# Z20K14xM register map
Vendor: Zhixin Semiconductor; Series: Z20K14xM; File version: 0.1.0
CPU: CM4 r0p1, little endian, no MPU, FPU, 4 interrupt priority bits
Registers are 32-bit, read-write, reset 0x0 unless marked. A register's access mark holds for its fields unless they carry their own. Offsets are from the block's base; [hi:lo] are bit positions; {n}, {i} and the like mark numbered series; 'fields as' and 'values as' point back to an identical list.

## PORT
Base 0x40049000
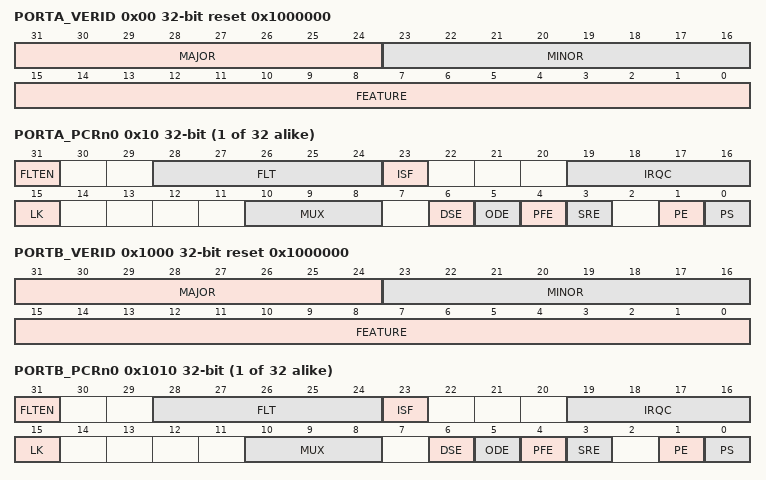
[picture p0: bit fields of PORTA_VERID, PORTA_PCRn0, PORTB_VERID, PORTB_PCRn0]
0x00 PORTA_VERID ro reset 0x1000000 — Port Version Number(PORTA_VERID)
  [31:24] MAJOR — Major Version Number
  [23:16] MINOR — Minor Version Number
  [15:0] FEATURE — Module Identification Number
0x04 PORTA_PARAM ro — PORT Parameter Register(PORTA_PARAM)
0x08 PORTA_GLBDAT — Global Pin Data Register(PORTA_GLBDAT)
  [31:0] GPWD — Global Pin Write Data
0x0C PORTA_GLBCTL wo — Global Pin Control Register(PORTA_GLBCTL)
  [31:0] GPWE — Global Pin Write Enable
{0x10+4i} PORTA_PCRn{i} (i=0..31) — Pin Control Register(PORTA_PCRn)
  [31] FLTEN — filter enable
  [28:24] FLT — filter configuration
  [23] ISF — Interrupt Status Flag
  [19:16] IRQC — Interrupt Configuration
  [15] LK — Lock Register
  [10:8] MUX — Pin Mux Control
  [6] DSE — Drive Strength Enable
  [5] ODE — Open Drain Enable
  [4] PFE — Passive Filter Enable
  [3] SRE — Slew Rate Enable
  [1] PE — Pull Enable
  [0] PS — Pull Select
0x90 PORTA_IRQFLG — Interrupt Status Flag Register (PORTA_IRQFLG)
  [31:0] ISF — Interrupt Status Flag
0x1000 PORTB_VERID ro reset 0x1000000 — Port Version Number(PORTB_VERID)
  fields as PORTA_VERID
0x1004 PORTB_PARAM ro — PORT Parameter Register(PORTB_PARAM)
0x1008 PORTB_GLBDAT — Global Pin Data Register(PORTB_GLBDAT)
  [31:0] GPWD — Global Pin Write Data
0x100C PORTB_GLBCTL wo — Global Pin Control Register(PORTB_GLBCTL)
  [31:0] GPWE — Global Pin Write Enable
{0x1010+4i} PORTB_PCRn{i} (i=0..31) — Pin Control Register(PORTB_PCRn)
  fields as PORTA_PCRn0
0x1090 PORTB_IRQFLG — Interrupt Status Flag Register (PORTB_IRQFLG)
  [31:0] ISF — Interrupt Status Flag
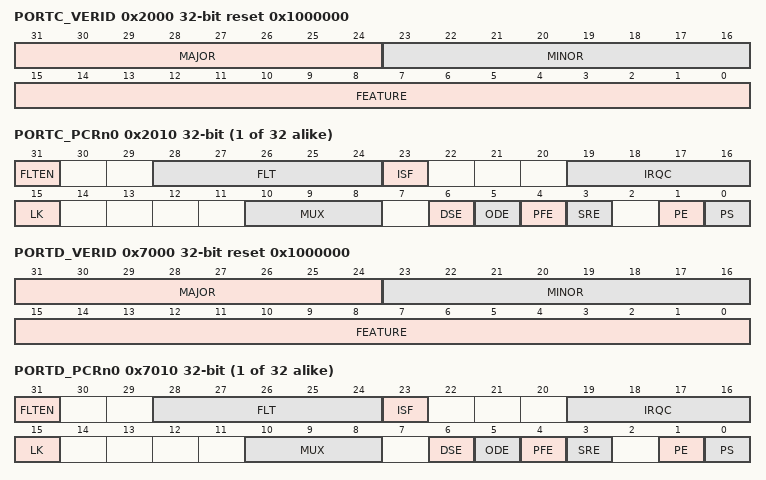
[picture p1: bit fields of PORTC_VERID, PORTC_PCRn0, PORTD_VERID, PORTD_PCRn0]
0x2000 PORTC_VERID ro reset 0x1000000 — Port Version Number(PORTC_VERID)
  fields as PORTA_VERID
0x2004 PORTC_PARAM ro — PORT Parameter Register(PORTC_PARAM)
0x2008 PORTC_GLBDAT — Global Pin Data Register(PORTC_GLBDAT)
  [31:0] GPWD — Global Pin Write Data
0x200C PORTC_GLBCTL wo — Global Pin Control Register(PORTC_GLBCTL)
  [31:0] GPWE — Global Pin Write Enable
{0x2010+4i} PORTC_PCRn{i} (i=0..31) — Pin Control Register(PORTC_PCRn)
  fields as PORTA_PCRn0
0x2090 PORTC_IRQFLG — Interrupt Status Flag Register (PORTC_IRQFLG)
  [31:0] ISF — Interrupt Status Flag
0x7000 PORTD_VERID ro reset 0x1000000 — Port Version Number(PORTD_VERID)
  fields as PORTA_VERID
0x7004 PORTD_PARAM ro — PORT Parameter Register(PORTD_PARAM)
0x7008 PORTD_GLBDAT — Global Pin Data Register(PORTD_GLBDAT)
  [31:0] GPWD — Global Pin Write Data
0x700C PORTD_GLBCTL wo — Global Pin Control Register(PORTD_GLBCTL)
  [31:0] GPWE — Global Pin Write Enable
{0x7010+4i} PORTD_PCRn{i} (i=0..31) — Pin Control Register(PORTD_PCRn)
  fields as PORTA_PCRn0
0x7090 PORTD_IRQFLG — Interrupt Status Flag Register (PORTD_IRQFLG)
  [31:0] ISF — Interrupt Status Flag
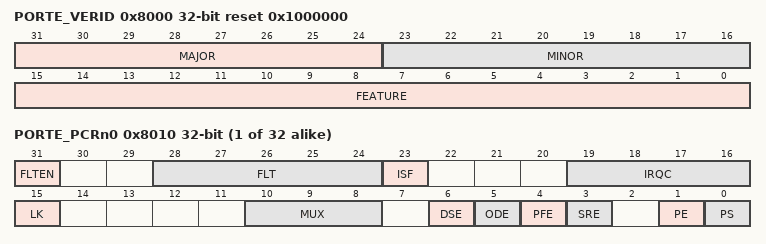
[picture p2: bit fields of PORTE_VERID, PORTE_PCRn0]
0x8000 PORTE_VERID ro reset 0x1000000 — Port Version Number(PORTE_VERID)
  fields as PORTA_VERID
0x8004 PORTE_PARAM ro — PORT Parameter Register(PORTE_PARAM)
0x8008 PORTE_GLBDAT — Global Pin Data Register(PORTE_GLBDAT)
  [31:0] GPWD — Global Pin Write Data
0x800C PORTE_GLBCTL wo — Global Pin Control Register(PORTE_GLBCTL)
  [31:0] GPWE — Global Pin Write Enable
{0x8010+4i} PORTE_PCRn{i} (i=0..31) — Pin Control Register(PORTE_PCRn)
  fields as PORTA_PCRn0
0x8090 PORTE_IRQFLG — Interrupt Status Flag Register (PORTE_IRQFLG)
  [31:0] ISF — Interrupt Status Flag

## WDOG
Base 0x40052000
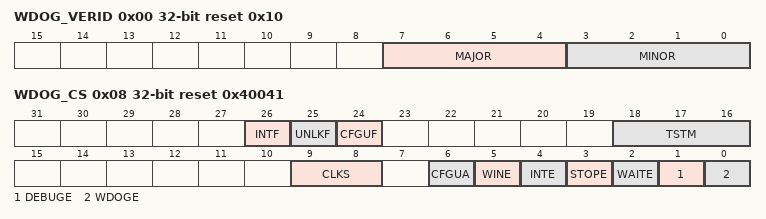
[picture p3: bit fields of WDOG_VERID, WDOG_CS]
0x00 WDOG_VERID ro reset 0x10 — Watchdog Version Idenfication(WDOG_VERID)
  [7:4] MAJOR — Major version
  [3:0] MINOR — Minor version
0x04 WDOG_PARAM ro reset 0x1 — Watchdog Parameter(WDOG_PARAM)
  [0] INT_PRESENT — Interrrupt function is present.
0x08 WDOG_CS reset 0x40041 — Watchdog Control and Status Registers(WDOG_CS)
  [26] INTF — Counter overflow interrupt flag. Write 1 to clear.
  [25] UNLKF — Flag indcates all registers are locked or unlocked.
  [24] CFGUF — Flag indcates configuration update is accompished.
  [18:16] TSTM — Fast test mode.
  [9:8] CLKS — wdog clock source
  [6] CFGUA — Configuration update allow.
  [5] WINE — Watchdog window mode enable.
  [4] INTE — Watchdog interrupt enable.
  [3] STOPE — Watchdog counter enabled in stop mode.
  [2] WAITE — Watchdog counter enabled in wait mode.
  [1] DEBUGE — Watchdog counter enabled in debug mode.
  [0] WDOGE — Watchdog enabled.
0x0C WDOG_TMO reset 0x1FFFF — Watchdog Timeout Register(WDOG_TMO)
  [31:0] TMO — Watchdog Timeout Value.
0x10 WDOG_WIN — Watchdog Window Register(WDOG_WIN)
  [31:0] WIN — Watchdog Window value.
0x14 WDOG_CNT — Watchdog Counter Register(WDOG_CNT)
  [31:0] CNT — Watchdog counter value.
